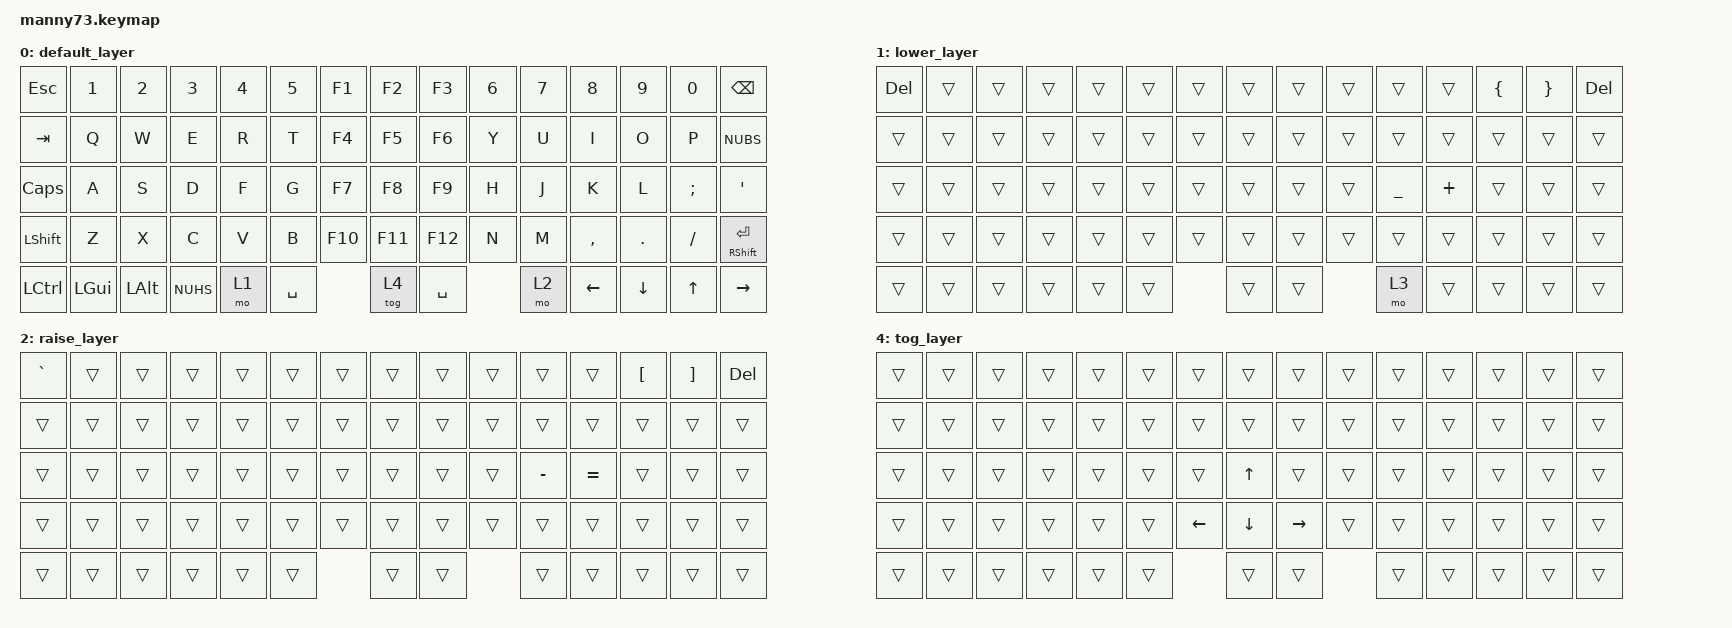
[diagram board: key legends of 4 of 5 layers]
#include <behaviors.dtsi>
#include <dt-bindings/zmk/keys.h>
#include <dt-bindings/zmk/bt.h>

/ {
    macros {
        unstick: unstick {
            compatible = "zmk,behavior-macro";
            #binding-cells = <0>;
            bindings
                = <&macro_release &kp LSHIFT &kp LCTRL &kp LALT &kp LGUI>
                , <&macro_release &kp RSHIFT &kp RCTRL &kp RALT &kp RGUI>
                ;
        };
    };
};

/ {
    keymap {
        compatible = "zmk,keymap";

        default_layer {
            // ------------------------------------------------------------------------------------------------------------------
            // |  ESC  |  1   |  2   |  3   |  4   |  5   |  F1   |  F2   |  F3   |   6   |  7    |  8   |  9   |   0   | BSPC  |
            // |  TAB  |  Q   |  W   |  E   |  R   |  T   |  F4   |  F5   |  F6   |   Y   |  U    |  I   |  O   |   P   |  \    |
            // |  CAPS |  A   |  S   |  D   |  F   |  G   |  F7   |  F8   |  F9   |   H   |  J    |  K   |  L   |   ;   |  '    |
            // |  SHFT |  Z   |  X   |  C   |  V   |  B   |  F10  |  F11  |  F12  |   N   |  M    |  ,   |  .   |   /   | ENTER |
            // |  CTRL | WIN  | ALT  |  ?   |  LWR |    Space     |  F13  |     Space     |  RSE  | LEFT | DOWN |   UP  | RIGHT |
            bindings = <
                &kp ESC    &kp N1   &kp N2    &kp N3   &kp N4   &kp N5   &kp F1  &kp F2  &kp F3   &kp N6 &kp N7   &kp N8    &kp N9  &kp N0    &kp BSPC
                &kp TAB    &kp Q    &kp W     &kp E    &kp R    &kp T    &kp F4  &kp F5  &kp F6   &kp Y  &kp U    &kp I     &kp O   &kp P     &kp NUBS
                &kp CAPS   &kp A    &kp S     &kp D    &kp F    &kp G    &kp F7  &kp F8  &kp F9   &kp H  &kp J    &kp K     &kp L   &kp SEMI  &kp SQT
                &kp LSHFT  &kp Z    &kp X     &kp C    &kp V    &kp B   &kp F10  &kp F11 &kp F12  &kp N  &kp M    &kp COMMA &kp DOT &kp FSLH  &mt RSHIFT ENTER
                &kp LCTRL  &kp LGUI &kp LALT  &kp NUHS &mo 1       &kp SPACE     &tog 4    &kp SPACE    &mo 2    &kp LEFT  &kp DOWN &kp UP   &kp RIGHT
            >;
        };

        lower_layer {
            bindings = <
                &kp DEL    &trans   &trans    &trans   &trans   &trans   &trans  &trans  &trans   &trans &trans   &trans    &kp LBRC &kp RBRC &kp DEL
                &trans     &trans   &trans    &trans   &trans   &trans   &trans  &trans  &trans   &trans &trans   &trans    &trans  &trans    &trans
                &trans     &trans   &trans    &trans   &trans   &trans   &trans  &trans  &trans   &trans &kp UNDER &kp PLUS &trans  &trans    &trans
                &trans     &trans   &trans    &trans   &trans   &trans   &trans  &trans  &trans   &trans &trans   &trans    &trans  &trans    &trans
                &trans     &trans   &trans    &trans   &trans        &trans      &trans      &trans      &mo 3   &trans    &trans  &trans    &trans
            >;
        };

        raise_layer {
            bindings = <
                &kp GRAVE  &trans   &trans    &trans   &trans   &trans   &trans  &trans  &trans   &trans &trans   &trans    &kp LBKT &kp RBKT &kp DEL
                &trans     &trans   &trans    &trans   &trans   &trans   &trans  &trans  &trans   &trans &trans   &trans    &trans  &trans    &trans
                &trans     &trans   &trans    &trans   &trans   &trans   &trans  &trans  &trans   &trans &kp MINUS &kp EQUAL &trans  &trans    &trans
                &trans     &trans   &trans    &trans   &trans   &trans   &trans  &trans  &trans   &trans &trans   &trans    &trans  &trans    &trans
                &trans     &trans   &trans    &trans   &trans        &trans      &trans      &trans      &trans   &trans    &trans  &trans    &trans
            >;
        };

        bt_layer {
              bindings = <
                &bootloader &bt BT_SEL 0   &bt BT_SEL 1     &bt BT_SEL 2   &none  &none  &none  &none  &none  &none  &none  &none  &none  &bt BT_CLR_ALL  &bt BT_CLR
                &none       &none          &none            &none          &sys_reset  &none  &none  &none  &none  &none  &unstick  &none  &none  &none  &none
                &none       &none          &none            &none          &none  &none  &none  &none  &none  &none  &none  &none  &none  &none  &none
                &kp GRAVE   &none          &none            &none          &none  &none  &none  &none  &none  &none  &none  &none  &none
            >;  
        };

        tog_layer {
            bindings = <
                &trans    &trans   &trans    &trans   &trans   &trans   &trans  &trans  &trans   &trans &trans   &trans     &trans  &trans    &trans
                &trans     &trans   &trans    &trans   &trans   &trans   &trans  &trans  &trans   &trans &trans   &trans    &trans  &trans    &trans
                &trans     &trans   &trans    &trans   &trans   &trans   &trans  &kp UP  &trans   &trans &trans   &trans    &trans  &trans    &trans
                &trans     &trans   &trans    &trans   &trans   &trans   &kp LEFT  &kp DOWN  &kp RIGHT   &trans &trans   &trans    &trans  &trans    &trans
                &trans     &trans   &trans    &trans   &trans        &trans      &trans      &trans      &trans   &trans    &trans  &trans    &trans
            >;
        };
    };
};
